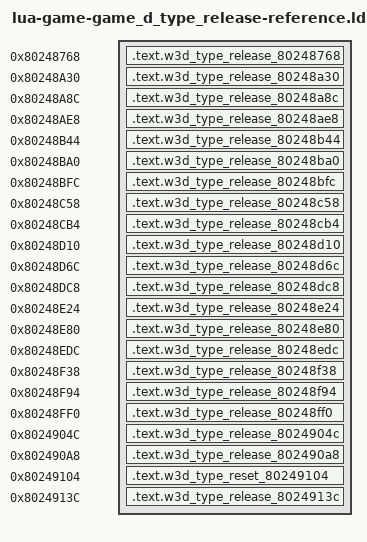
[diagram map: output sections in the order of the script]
/* Generated reference-only placements. All bodies are source-built. */
OUTPUT_FORMAT("elf32-powerpc")
OUTPUT_ARCH(powerpc)
ENTRY(w3d_type_release_80248768)
_SDA_BASE_ = 0x804b2540;
_SDA2_BASE_ = 0x804c2540;
w3d_type_destroy_80241e4c = 0x80241e4c;
w3d_type_destroy_80242910 = 0x80242910;
w3d_type_destroy_80242cd0 = 0x80242cd0;
w3d_type_destroy_802432a8 = 0x802432a8;
w3d_type_destroy_802442fc = 0x802442fc;
w3d_type_destroy_80244588 = 0x80244588;
w3d_type_destroy_802447d0 = 0x802447d0;
w3d_type_destroy_80244d60 = 0x80244d60;
w3d_type_destroy_8024583c = 0x8024583c;
w3d_type_destroy_80245a58 = 0x80245a58;
w3d_type_destroy_80245d58 = 0x80245d58;
w3d_type_destroy_802463b8 = 0x802463b8;
w3d_type_destroy_80246cbc = 0x80246cbc;
w3d_type_destroy_80247000 = 0x80247000;
w3d_type_destroy_802473fc = 0x802473fc;
w3d_type_destroy_802475ac = 0x802475ac;
w3d_type_destroy_802477a8 = 0x802477a8;
w3d_type_destroy_802479b8 = 0x802479b8;
w3d_type_destroy_80247c9c = 0x80247c9c;
w3d_type_destroy_80247e5c = 0x80247e5c;
w3d_type_destroy_802480f0 = 0x802480f0;
w3d_type_unlink_80241b68 = 0x80241b68;
w3d_type_unlink_802427f4 = 0x802427f4;
w3d_type_unlink_80242c30 = 0x80242c30;
w3d_type_unlink_80242e78 = 0x80242e78;
w3d_type_unlink_80244230 = 0x80244230;
w3d_type_unlink_802444e8 = 0x802444e8;
w3d_type_unlink_80244730 = 0x80244730;
w3d_type_unlink_80244978 = 0x80244978;
w3d_type_unlink_80245778 = 0x80245778;
w3d_type_unlink_802459a0 = 0x802459a0;
w3d_type_unlink_80245c40 = 0x80245c40;
w3d_type_unlink_8024605c = 0x8024605c;
w3d_type_unlink_80246bf4 = 0x80246bf4;
w3d_type_unlink_80246ed8 = 0x80246ed8;
w3d_type_unlink_80247374 = 0x80247374;
w3d_type_unlink_80247500 = 0x80247500;
w3d_type_unlink_80247720 = 0x80247720;
w3d_type_unlink_802478ac = 0x802478ac;
w3d_type_unlink_80247c14 = 0x80247c14;
w3d_type_unlink_80247da0 = 0x80247da0;
w3d_type_unlink_80248010 = 0x80248010;
SECTIONS {
  .text.w3d_type_release_80248768 0x80248768 : { *(.text.w3d_type_release_80248768) }
  .text.w3d_type_release_80248a30 0x80248a30 : { *(.text.w3d_type_release_80248a30) }
  .text.w3d_type_release_80248a8c 0x80248a8c : { *(.text.w3d_type_release_80248a8c) }
  .text.w3d_type_release_80248ae8 0x80248ae8 : { *(.text.w3d_type_release_80248ae8) }
  .text.w3d_type_release_80248b44 0x80248b44 : { *(.text.w3d_type_release_80248b44) }
  .text.w3d_type_release_80248ba0 0x80248ba0 : { *(.text.w3d_type_release_80248ba0) }
  .text.w3d_type_release_80248bfc 0x80248bfc : { *(.text.w3d_type_release_80248bfc) }
  .text.w3d_type_release_80248c58 0x80248c58 : { *(.text.w3d_type_release_80248c58) }
  .text.w3d_type_release_80248cb4 0x80248cb4 : { *(.text.w3d_type_release_80248cb4) }
  .text.w3d_type_release_80248d10 0x80248d10 : { *(.text.w3d_type_release_80248d10) }
  .text.w3d_type_release_80248d6c 0x80248d6c : { *(.text.w3d_type_release_80248d6c) }
  .text.w3d_type_release_80248dc8 0x80248dc8 : { *(.text.w3d_type_release_80248dc8) }
  .text.w3d_type_release_80248e24 0x80248e24 : { *(.text.w3d_type_release_80248e24) }
  .text.w3d_type_release_80248e80 0x80248e80 : { *(.text.w3d_type_release_80248e80) }
  .text.w3d_type_release_80248edc 0x80248edc : { *(.text.w3d_type_release_80248edc) }
  .text.w3d_type_release_80248f38 0x80248f38 : { *(.text.w3d_type_release_80248f38) }
  .text.w3d_type_release_80248f94 0x80248f94 : { *(.text.w3d_type_release_80248f94) }
  .text.w3d_type_release_80248ff0 0x80248ff0 : { *(.text.w3d_type_release_80248ff0) }
  .text.w3d_type_release_8024904c 0x8024904c : { *(.text.w3d_type_release_8024904c) }
  .text.w3d_type_release_802490a8 0x802490a8 : { *(.text.w3d_type_release_802490a8) }
  .text.w3d_type_reset_80249104 0x80249104 : { *(.text.w3d_type_reset_80249104) }
  .text.w3d_type_release_8024913c 0x8024913c : { *(.text.w3d_type_release_8024913c) }
  /DISCARD/ : { *(.text*) *(.rodata*) *(.data*) *(.bss*) *(.sdata*) *(.sbss*) *(.comment) }
}
